# ADuCM362 register map
Vendor: Analog Devices Inc.; Series: ADuCM36x; File version: 0.1
CPU: CM3 r2p1, little endian, no MPU, no FPU, 3 interrupt priority bits
Registers are 16-bit, read-write, no defined reset value unless marked. A register's access mark holds for its fields unless they carry their own. Offsets are from the block's base; [hi:lo] are bit positions; {n}, {i} and the like mark numbered series.

## ADI_UART0 — UART0
Base 0x40005000
Same registers: ADI_UART1 0x40005400, ADI_UART2 0x40005800
0x00 COMTX 8-bit wo — Transmit Holding register
  [7:0] VALUE range 0x00000000..0x000000FF
0x00 COMRX 8-bit ro (alternate view of COMTX) — Receive Buffer register
  [7:0] VALUE range 0x00000000..0x000000FF
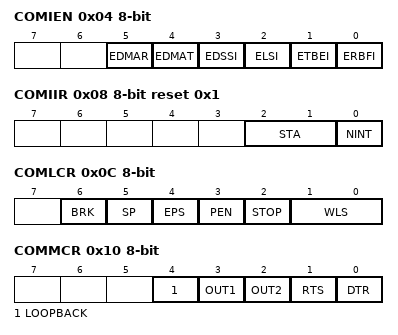
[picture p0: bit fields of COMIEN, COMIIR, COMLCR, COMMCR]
0x04 COMIEN 8-bit — Interrupt Enable register
  [all] fields
    0=DIS; 1=EN
  [5] EDMAR — Enable DMA requests in transmit mode
  [4] EDMAT — Enable DMA requests in receive mode
  [3] EDSSI — Enable Modem Status interrupt
  [2] ELSI — Enable Rx status interrupt
  [1] ETBEI — Enable transmit buffer empty interrupt
  [0] ERBFI — Enable receive buffer full interrupt
0x08 COMIIR 8-bit ro reset 0x1 (reset mask 0x0) — Interrupt Identification register
  [2:1] STA — Status bits.
    0=MODEMSTATUS (- Modem status interrupt.); 1=TXBUFEMPTY (- Transmit buffer empty interrupt.); 2=RXBUFFULL (- Receive buffer full interrupt. Read RBR register to clear.); 3=RXLINESTATUS (- Receive line status interrupt. Read LSR register to clear.)
  [0] NINT — Interrupt flag.
    0=CLR; 1=SET
0x0C COMLCR 8-bit — Line Control register
  [6] BRK — Set Break.
    0=DIS; 1=EN
  [5] SP — Stick Parity.
    0=DIS; 1=EN
  [4] EPS — Even Parity Select Bit.
    0=DIS; 1=EN
  [3] PEN — Parity Enable Bit.
    0=DIS; 1=EN
  [2] STOP — Stop Bit.
    0=DIS; 1=EN
  [1:0] WLS — Word Length Select bits
    {v}={v+5}BITS (v=0..3)
0x10 COMMCR 8-bit — Module Control register
  [all] fields
    0=DIS; 1=EN
  [4] LOOPBACK
  [3] OUT1 — Parity Enable Bit.
  [2] OUT2 — Stop Bit.
  [1] RTS — Request To Send.
  [0] DTR — Data Terminal Ready.
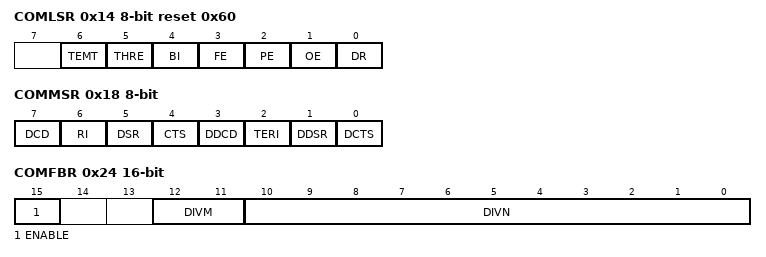
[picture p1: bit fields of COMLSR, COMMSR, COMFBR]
0x14 COMLSR 8-bit ro reset 0x60 (reset mask 0x0) — Line Status register
  [all] fields
    0=CLR; 1=SET
  [6] TEMT — COMTX and Shift Register Empty Status Bit.
  [5] THRE — COMTX Empty Status Bit.
  [4] BI — Break Indicator.
  [3] FE — Framing Error.
  [2] PE — Parity Error.
  [1] OE — Overrun Error.
  [0] DR — Data Ready.
0x18 COMMSR 8-bit ro — Modem Status register
  [all] fields
    0=DIS; 1=EN
  [7] DCD — Data Carrier Detect.
  [6] RI — Ring Indicator.
  [5] DSR — Data Set Ready.
  [4] CTS — Clear To Send.
  [3] DDCD — Delta DCD.
  [2] TERI — Trailing Edge RI.
  [1] DDSR — Delta DSR.
  [0] DCTS — Delta CTS.
0x24 COMFBR — Fractional baud rate divider register.
  [15] ENABLE
    0=DIS; 1=EN
  [12:11] DIVM range 0x00000000..0x00000003 — Fractional M Divide bits
  [10:0] DIVN range 0x00000000..0x000007FF — Fractional N Divide bits
0x28 COMDIV reset 0x1 (reset mask 0x0) — Baud rate Divisor register
  [15:0] VALUE range 0x00000000..0x0000FFFF — Sets the baudrate
0x30 COMCON 8-bit — UART control register
  [0] DISABLE — Uart Disable
    0=DIS; 1=EN

## ADI_GPIO0 — General Purpose Input Output
Base 0x40006000
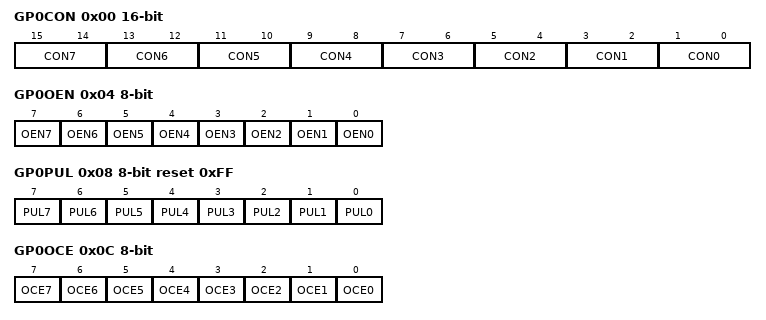
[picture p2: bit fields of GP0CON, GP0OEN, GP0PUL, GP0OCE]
0x00 GP0CON — GPIO Port 0 configuration
  [15:14] CON7 — Configuration bits for P0.7
    0=PORB; 1=GPIO; 2=UARTTXD
  [13:12] CON6 — Configuration bits for P0.6
    0=GPIOIRQ2; 1=UARTRXD
  [11:10] CON5 — Configuration bits for P0.5
    0=GPIOIRQ1; 1=UARTCTS
  [9:8] CON4 — Configuration bits for P0.4
    0=GPIO; 1=UARTRTS; 2=ECLKOUT
  [7:6] CON3 — Configuration bits for P0.3
    0=GPIOIRQ0; 1=SPI1CS0
  [5:4] CON2 — Configuration bits for P0.2
    0=GPIO; 1=SPI1MOSI; 2=I2CSDA; 3=UARTTXD
  [3:2] CON1 — Configuration bits for P0.1
    0=GPIO; 1=SPI1SCLK; 2=I2CSCL; 3=UARTRXD
  [1:0] CON0 — Configuration bits for P0.0
    0=GPIO; 1=SPI1MISO
0x04 GP0OEN 8-bit — GPIO Port 0 output enable
  [all] fields
    0=IN; 1=OUT
  [n] OEN{n} (n=0..7) — Direction for port pin
0x08 GP0PUL 8-bit reset 0xFF (reset mask 0x0) — GPIO Port 0 output pull up enable.
  [all] fields
    0=DIS; 1=EN
  [n] PUL{n} (n=0..7) — Pull Up Enable for port pin
0x0C GP0OCE 8-bit — GPIO Port 0 tri state
  [all] fields
    0=DIS; 1=EN
  [n] OCE{n} (n=0..7) — open circuit Enable for port pin
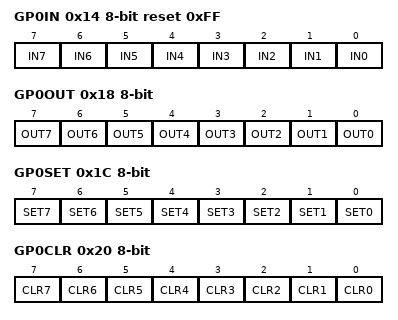
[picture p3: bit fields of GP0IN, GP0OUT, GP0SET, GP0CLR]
0x14 GP0IN 8-bit ro reset 0xFF (reset mask 0x0) — GPIO Port 0 data input.
  [all] fields
    0=LOW; 1=HIGH
  [n] IN{n} (n=0..7) — Input for port pin
0x18 GP0OUT 8-bit — GPIO Port 0 data out.
  [all] fields
    0=LOW; 1=HIGH
  [n] OUT{n} (n=0..7) — Output for port pin
0x1C GP0SET 8-bit wo — GPIO Port 0 data out set
  [all] fields
    1=SET
  [n] SET{n} (n=0..7) — Set Output High for port pin
0x20 GP0CLR 8-bit wo — GPIO Port 0 data out clear.
  [all] fields
    1=CLR
  [n] CLR{n} (n=0..7) — Set Output Low for port pin
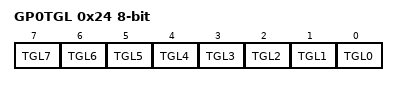
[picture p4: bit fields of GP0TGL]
0x24 GP0TGL 8-bit wo — GPIO Port 0 pin toggle.
  [all] fields
    1=TGL
  [n] TGL{n} (n=0..7) — Toggle Output for port pin
